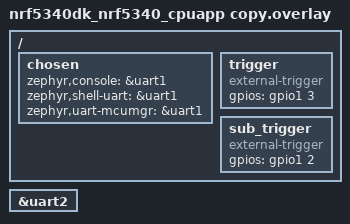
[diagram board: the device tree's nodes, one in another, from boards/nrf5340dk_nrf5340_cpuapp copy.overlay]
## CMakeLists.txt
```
# SPDX-License-Identifier: Apache-2.0

cmake_minimum_required(VERSION 3.20.0)

find_package(Zephyr REQUIRED HINTS $ENV{ZEPHYR_BASE})
project(ceva)

FILE(GLOB app_sources src/*.c)
target_sources(app PRIVATE ${app_sources})
```

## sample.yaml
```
sample:
  name: CEVA application
tests:
  applications.ceva:
    integration_platforms:
      - qemu_x86
    tags:
      - serial
      - uart
    filter: CONFIG_SERIAL and
            CONFIG_UART_INTERRUPT_DRIVEN and
            dt_chosen_enabled("zephyr,shell-uart")
    harness: keyboard
```

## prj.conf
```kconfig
CONFIG_CRYPTO=y
CONFIG_SERIAL=y
CONFIG_GPIO=y
CONFIG_UART_INTERRUPT_DRIVEN=y
CONFIG_NEWLIB_LIBC=y
CONFIG_MAIN_STACK_SIZE=4096
CONFIG_BOOT_BANNER=n

CONFIG_MBEDTLS=y
CONFIG_MBEDTLS_BUILTIN=y
CONFIG_MBEDTLS_HEAP_SIZE=512
CONFIG_MBEDTLS_CIPHER_CCM_ENABLED=y
CONFIG_MBEDTLS_CIPHER_GCM_ENABLED=y
CONFIG_CRYPTO_MBEDTLS_SHIM=y


# CONFIG_BOARD_ENABLE_DCDC_APP=n 
# CONFIG_BOARD_ENABLE_DCDC_NET=n 
# CONFIG_BOARD_ENABLE_DCDC_HV=n 
```

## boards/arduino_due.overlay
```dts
/*
 * Copyright (c) 2023 Laurent Bonnet
 *
 * SPDX-License-Identifier: Apache-2.0
 */

/**
 * trigger 0 = D12, PD8 
 * trigger 1 = D11, PD7
 */

/ {
	trigger: trigger {
		compatible = "external-trigger";
		gpios = <&piod 8 0>;
	};
	sub_trigger: sub_trigger {
		compatible = "external-trigger";
		gpios = <&piod 7 0>;
	};	
};

&piod {
	status="okay";
};
```

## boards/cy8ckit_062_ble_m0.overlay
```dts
/*
 * Copyright (c) 2023 Laurent Bonnet
 *
 * SPDX-License-Identifier: Apache-2.0
 */

/*
 * Map trigger to D7 in arduino header 
 * Refer to cy8ckit_062_common.dtsi
 */

/ {
	trigger: trigger {
		compatible = "external-trigger";
		gpios = <&gpio_prt0 2 GPIO_ACTIVE_HIGH>;
	};
	sub_trigger: sub_trigger {
		compatible = "external-trigger";
		gpios = <&gpio_prt0 3 GPIO_ACTIVE_HIGH>;
	};	
};
```

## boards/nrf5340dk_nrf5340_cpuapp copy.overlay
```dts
/*
 * Copyright (c) 2023 Laurent Bonnet
 *
 * SPDX-License-Identifier: Apache-2.0
 */

/ {
	chosen {
		zephyr,console = &uart1;
		zephyr,shell-uart = &uart1;
		zephyr,uart-mcumgr = &uart1;
	};
	
	trigger: trigger {
		compatible = "external-trigger";
		gpios = <&gpio1 3 GPIO_ACTIVE_HIGH>;
	};
	sub_trigger: sub_trigger {
		compatible = "external-trigger";
		gpios = <&gpio1 2 GPIO_ACTIVE_HIGH>;
	};	
};

&uart2 {
	status="okay";
};
```

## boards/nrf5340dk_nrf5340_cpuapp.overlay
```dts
/*
 * Copyright (c) 2023 Laurent Bonnet
 *
 * SPDX-License-Identifier: Apache-2.0
 */

/ {
	chosen {
		zephyr,console = &uart1;
		zephyr,shell-uart = &uart1;
		zephyr,uart-mcumgr = &uart1;
	};

	trigger: trigger {
		compatible = "external-trigger";
		gpios = <&gpio1 3 GPIO_ACTIVE_HIGH>;
	};
	sub_trigger: sub_trigger {
		compatible = "external-trigger";
		gpios = <&gpio1 2 GPIO_ACTIVE_HIGH>;
	};	
};

&uart1 {
	status="okay";
};
```

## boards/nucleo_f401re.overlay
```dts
/*
 * Copyright (c) 2023 Laurent Bonnet
 *
 * SPDX-License-Identifier: Apache-2.0
 */

/**
 * trigger 0 = D10, PB6  CN5.3
 * trigger 1 = D6,  PB10 CN9.7
 */

/ {
	trigger: trigger {
		compatible = "external-trigger";
		gpios = <&gpiob 6 GPIO_ACTIVE_HIGH>;
	};
	sub_trigger: sub_trigger {
		compatible = "external-trigger";
		gpios = <&gpiob 10 GPIO_ACTIVE_HIGH>;
	};
};
```

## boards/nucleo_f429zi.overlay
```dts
/*
 * Copyright (c) 2023 Laurent Bonnet
 *
 * SPDX-License-Identifier: Apache-2.0
 */

/**
 * trigger 0 = D28, PD13  CN10.19
 * trigger 1 = D30,  PD11  CN10.23
 */

/ {
	trigger: trigger {
		compatible = "external-trigger";
		gpios = <&gpiod 13 GPIO_ACTIVE_HIGH>;
	};
	sub_trigger: sub_trigger {
		compatible = "external-trigger";
		gpios = <&gpiod 11 GPIO_ACTIVE_HIGH>;
	};
};
```

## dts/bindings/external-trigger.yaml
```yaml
# Copyright (c) 2023 Laurent Bonnet
# SPDX-License-Identifier: Apache-2.0

description: GPIO pin to trigger external equipment

compatible: "external-trigger"

properties:
  gpios:
    type: phandle-array
    required: true
    description: |
      The GPIO used to trigger external equipment
```

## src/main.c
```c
/*
 * Copyright (c) 2023 Laurent Woolcap
 *
 * SPDX-License-Identifier: Apache-2.0
 */
#include <zephyr/device.h>
#include <zephyr/kernel.h>
#include <zephyr/sys/sys_heap.h>
#include <zephyr/kernel_version.h>
#include <zephyr/drivers/uart.h>
#include <zephyr/crypto/crypto.h>
#include <zephyr/drivers/gpio.h>

#include <string.h>
#include <stdio.h>
#include "main.h"
#include "simply_aes.h"
#include "utils.h"

#ifdef CONFIG_CRYPTO_TINYCRYPT_SHIM
#define CRYPTO_DRV_NAME CONFIG_CRYPTO_TINYCRYPT_SHIM_DRV_NAME
#elif CONFIG_CRYPTO_MBEDTLS_SHIM
#define CRYPTO_DRV_NAME CONFIG_CRYPTO_MBEDTLS_SHIM_DRV_NAME
#elif DT_HAS_COMPAT_STATUS_OKAY(st_stm32_cryp)
#define CRYPTO_DEV_COMPAT st_stm32_cryp
#elif DT_HAS_COMPAT_STATUS_OKAY(st_stm32_aes)
#define CRYPTO_DEV_COMPAT st_stm32_aes
#elif DT_HAS_COMPAT_STATUS_OKAY(nxp_mcux_dcp)
#define CRYPTO_DEV_COMPAT nxp_mcux_dcp
#elif CONFIG_CRYPTO_NRF_ECB
#define CRYPTO_DEV_COMPAT nordic_nrf_ecb
#else
#error "You need to enable one crypto device"
#endif

/* change this to any other UART peripheral if desired */
#define UART_DEVICE_NODE DT_CHOSEN(zephyr_shell_uart)

/* Message size in characters*/
#define MSG_CHAR_SIZE 512
#define MSG_BYTE_SIZE (MSG_CHAR_SIZE	>>	2)
#define MSG_WORD_SIZE (MSG_BYTE_SIZE	>>	2)

#define version "0.1.0"

/* queue to store up to 10 messages (aligned to 4-byte boundary) */
K_MSGQ_DEFINE(uart_msgq, MSG_CHAR_SIZE, 10, 4);

static const struct device *const uart_dev = DEVICE_DT_GET(UART_DEVICE_NODE);

/* device tree for led */
#define LED0_NODE DT_ALIAS(led0)
static const struct gpio_dt_spec led = GPIO_DT_SPEC_GET(LED0_NODE, gpios);

/* receive buffer used in UART ISR callback */
static char rx_buf[MSG_CHAR_SIZE];
static int rx_buf_pos;
uint32_t cap_flags;
const struct device *dev;

/**
 * @brief header structure 
 */
struct header {
	uint8_t cla;
	uint8_t ins;
	uint8_t p1;	
	uint8_t p2;
	uint16_t length;
	union  {
		uint8_t byte[MSG_BYTE_SIZE - 6];
		uint16_t word[MSG_WORD_SIZE - 3];
	} data;
};

struct header * command;
uint8_t out[MSG_BYTE_SIZE];

/**
 * @brief swap 16bit value
 * @param val input value
 * @return uint16_t 
 */
uint16_t swap16(uint16_t val) {
    return ((val << 8) | (val >> 8 ));
}

/**
 * @brief Read characters from UART until line end is detected. Afterwards push the
 * data to the message queue.
 * @param dev pointer on device
 * @param user_data pointer on message data
 */
void read(const struct device *dev, void *user_data) {
	uint8_t c;

	if (!uart_irq_update(uart_dev)) {
		return;
	}

	if (!uart_irq_rx_ready(uart_dev)) {
		return;
	}

	/* read until FIFO empty */
	while (uart_fifo_read(uart_dev, &c, 1) == 1) {
		if ((c == '\n' || c == '\r') && rx_buf_pos > 0) {
			/* terminate string */
			rx_buf[rx_buf_pos] = '\0';

			/* if queue is full, message is silently dropped */
			k_msgq_put(&uart_msgq, &rx_buf, K_NO_WAIT);

			/* reset the buffer (it was copied to the msgq) */
			rx_buf_pos = 0;
		} else if (rx_buf_pos < (sizeof(rx_buf) - 1)) {
			rx_buf[rx_buf_pos++] = c;
		}
		/* else: characters beyond buffer size are dropped */
	}
}

/**
 * @brief a null-terminated string character by character to the UART interface
 * @param buf pointer on output buffer
 */
void send(char *buf) {
	int lenght = strlen(buf);
	for (int i = 0; i < lenght; i++) {
		uart_poll_out(uart_dev, buf[i]);
	}
}

/**
 * @brief basic check of the command string, and byte convertion
 * @param in pointer on input string
 * @param out pointer on output byte array.
 */
int check(char *in, uint8_t *out) {
	// Get lenght
	int length = strlen(in);
	if ((length < 12) || (length % 2 != 0))
		return -1;
    for (int i = 0; i < length; i++)
    {
        // Reads in & stores in out
        sscanf(in, "%2hhx", &out[i]);
        in += 2;
    }
	// cast to header structure
 	command = (struct header * )out;
	// convert length
	command->length = swap16(command->length);
	// check length consistency with data received
	if (((length / 2) - command->length) != 6) {
		return -2;
	}
	return 0;
}

/**
 * @brief while loop command
 * @param iteration loop index max value
 */
void while_loop(uint16_t iteration) {
	uint16_t index, count = 0;
	char result[24];
	index = iteration;

	trigger_high();
	while(index) {
		index--;
		count++;
	}
	trigger_low();
	sprintf(result, "%04X%04X9000\r\n",index,count);
	send(result);
}

/**
 * @brief for loop command
 * @param iteration loop index max value
 */
void for_loop(uint16_t iteration) {
	char result[24];
	uint16_t index, count = 0;

	trigger_high();
	for (index = 0; index < iteration; index++) {
		count ++;
	}
	trigger_low();

	sprintf(result, "%04X%04X9000\r\n",index,count);
	send(result);
}

/**
 * @brief encrypt with simply aes command
 * @param data pointer on data in
 */
void simply_aes(uint8_t * data) {
	uint8_t result[2 * 16 + 4];
	uint8_t offset = 0;
	simple_aes_init(data);
	
	trigger_high();
	simple_aes_cipher();
	trigger_low();
	
	simple_aes_final(data);

	for (int i=0; i < 16; i++) {
		offset += sprintf(result + offset, "%02X", data[i]);
	}
	sprintf(result + offset, "9000\r\n");
	send(result);
}

/**
 *  @brief
 */
int validate_hw_compatibility(const struct device *dev)
{
	uint32_t flags = 0U;

	flags = crypto_query_hwcaps(dev);
	if ((flags & CAP_RAW_KEY) == 0U) {
		printk("Please provision the key separately as the module doesnt support a raw key");
		return -1;
	}

	if ((flags & CAP_SYNC_OPS) == 0U) {
		printk("The app assumes sync semantics. Please rewrite the app accordingly before proceeding");
		return -1;
	}

	if ((flags & CAP_SEPARATE_IO_BUFS) == 0U) {
		printk("The app assumes distinct IO buffers. Please rewrite the app accordingly before proceeding");
		return -1;
	}

	cap_flags = CAP_RAW_KEY | CAP_SYNC_OPS | CAP_SEPARATE_IO_BUFS;

	return 0;

}

/**
 * @brief aes encrypt ecb mode
 * @param data pointer data in
 */
void encrypt_aes_ebc(uint8_t * data) {
	uint8_t result[2 * 16 + 6];
	uint8_t offset = 0;
	uint8_t encrypted[16] = {0};

	struct cipher_ctx ini = {
		.keylen = 16,
		.key.bit_stream = data,
		.flags = cap_flags,
	};
	struct cipher_pkt encrypt = {
		.in_buf = &data[16],
		.in_len = 16,
		.out_buf_max = sizeof(encrypted),
		.out_buf = encrypted,
	};
	if (cipher_begin_session(dev, &ini, CRYPTO_CIPHER_ALGO_AES,
				 CRYPTO_CIPHER_MODE_ECB,
				 CRYPTO_CIPHER_OP_ENCRYPT)) {
		return;
	}
	trigger_high();
	if (cipher_block_op(&ini, &encrypt)) {
		goto out;
	}
	trigger_low();
	for (int i=0; i < 16; i++) {
		offset += sprintf(result + offset, "%02X", encrypt.out_buf[i]);
	}
	sprintf(result + offset, "9000\r\n");
	send(result);
out:
	cipher_free_session(dev, &ini);	
}

/**
 * @brief Dispatch command
 * @param pointer to input buffer
 */
int dispatch(char *in) {
	int status = 0;
	uint32_t v;

	// start watchdog

	// check input data
	status = check(in,out);
	
	if (status==0) {
		if (command->cla != CLASS)
			send("6E00\r\n");
		else {
			switch (command->ins) {
				case INS_GET_INFO:
					v = sys_kernel_version_get();

					printk("Chip evaluation Zephir Kernel= %d.%d.%d, board= %s, firmware version=%s\r\n", SYS_KERNEL_VER_MAJOR(v),SYS_KERNEL_VER_MINOR(v), SYS_KERNEL_VER_PATCHLEVEL(v),CONFIG_BOARD,version);
					break; 

				case INS_LOOP:
					if (command->length != 2)
						send("6700\r\n");
					else {
						if (command->p1==LOOP_FOR) {
							// call for loop process
							for_loop(command->data.word[0]);
						} else if (command->p1==LOOP_WHILE) {
							// call while loop process
							while_loop(command->data.word[0]);
						} else {
							send("6A00\r\n");
						}
					}
					break;
				case INS_CRYPTO:
					if (command->length != 32)
						send("6700\r\n");
					else
						if (command->p1==SIMPLY_ENCRYPT_AES_ECB) {
							simply_aes(command->data.byte);							
						} else if (command->p1==DRIVER_ENCRYPT_AES_ECB) {
							encrypt_aes_ebc(command->data.byte);
						} else {
							send("6A00\r\n");
						}
					break;

				default:
					send("6986\r\n");
					break;
			}
		}
	}
	if (status==-1) {
		send("6F01\r\n");
	}

	if (status==-2) {
		send("6700\r\n");
	}
	// stop watchdog
	
	return 0;
}

/**
 * 
 */
int main(void)
{
	char cmd_buf[MSG_CHAR_SIZE];

#ifdef CRYPTO_DRV_NAME
	dev = device_get_binding(CRYPTO_DRV_NAME);
	if (!dev) {
		printk("%s pseudo device not found", CRYPTO_DRV_NAME);
		return 0;
	}
#else
	dev = DEVICE_DT_GET_ONE(CRYPTO_DEV_COMPAT);

	if (!device_is_ready(dev)) {
		printk("Crypto device is not ready\n");
		return 0;
	}
#endif

	if (!device_is_ready(uart_dev)) {
		printk("UART device not found!");
		return 0;
	}
	if (validate_hw_compatibility(dev)) {
		printk("Incompatible crypto h/w");
		return 0;
	}
	/* configure interrupt and callback to receive data */
	int ret = uart_irq_callback_user_data_set(uart_dev, read, NULL);

	if (ret < 0) {
		if (ret == -ENOTSUP) {
			printk("Interrupt-driven UART API support not enabled\n");
		} else if (ret == -ENOSYS) {
			printk("UART device does not support interrupt-driven API\n");
		} else {
			printk("Error setting UART callback: %d\n", ret);
		}
		return 0;
	}

	uart_irq_rx_enable(uart_dev);

	/* Set led0 */
	if (!gpio_is_ready_dt(&led)) {
		printk("Error indicator not ready...");
		return 0;
	}

	ret = gpio_pin_configure_dt(&led, GPIO_OUTPUT_ACTIVE);
	if (ret < 0) {
		printk("Error indicator configuration...");
		return 0;
	}

	ret = gpio_pin_set_dt(&led, 1);
	if (ret < 0) {
		printk("Error indicator toggle...");
		return 0;
	}

	ret = trigger_init();
	if (ret < 0) {
		printk("Error trigger init...");
		return 0;
	}

	/* indefinitely wait for input from the user */
	while (k_msgq_get(&uart_msgq, &cmd_buf, K_FOREVER) == 0) {	
		dispatch(cmd_buf);
	}
	return 0;
}
```

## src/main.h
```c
/**
 * @file main.h
 * @author Laurent Bonnet (laurent.woolcap@free.fr)
 * @brief Chip evaluation firmware, main interface file
 * @copyright Copyright (c) 2024
 */
#define CLASS                   0xFE /*!< Command Class byte */

#define INS_GET_INFO            0x80 /*!< Get info instruction byte */

/**
 * @brief loop instructions
 */
#define INS_LOOP                0x86 /*!< Loop Instruction byte */
#define LOOP_FOR                0x02 /*!< P1 Parameter: for loop */
#define LOOP_WHILE              0x04 /*!< P1 Parameter: while loop */

/**
 * @brief Cryptographic instructions
 */
#define INS_CRYPTO              0x8A /*!< Crypto Instruction byte */
#define SIMPLY_ENCRYPT_AES_ECB  0x02 /*!< AES ECB SIMPLY */
#define DRIVER_ENCRYPT_AES_ECB  0x04 /*!< AES ECB MBEDTLS */
```

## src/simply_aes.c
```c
/**
 * @file simply_aes.c
 * @author laurent bonnet (laurent.woolcap@free.fr)
 * @brief Chip Evaluation firmware, Simple software AES
 * @copyright Copyright (c) 2023
 */
#define __UL_AES_C
#include "simply_aes.h"
#include "utils.h"

static  const int Sbox    [256] = _Sub;
const int xtimes  [256] = _xt;
static  const int rcon[10] = {0x01, 0x02, 0x04, 0x08, 0x10, 0x20, 0x40, 0x80, 0x1b, 0x36};
int rk[176];
int state[16];
int tmp[2];
int *pt_rk;

/**
 * @brief key expansion
 */
static void key_expansion(void)
{
  int i;
  for(i=16;i<176;i+=4){
    
    if ((i&0xF)==0){
      state[0] = Sbox[rk[i-3]] ^ rcon[(i/16)-1];
      state[1] = Sbox[rk[i-2]];
      state[2] = Sbox[rk[i-1]];
      state[3] = Sbox[rk[i-4]];
    }
    
    else{
      state[0] = rk[i-4];
      state[1] = rk[i-3];
      state[2] = rk[i-2];
      state[3] = rk[i-1];
    }
    
    rk[i  ] = rk[i-16] ^ state[0];
    rk[i+1] = rk[i-15] ^ state[1];
    rk[i+2] = rk[i-14] ^ state[2];
    rk[i+3] = rk[i-13] ^ state[3];
  }
}

/**
 * @brief Add round Key
 */
static void AddRoundKey(void)
{
  int j;
  for(j=0;j<16;j++){
    state[j] ^= pt_rk[j];
  }
}

/**
 * @brief subbytes and shiftrow operation
 */
static void SubBytes_ShiftRows(void)
{
  state[ 0] = Sbox[state[ 0]];
  state[ 4] = Sbox[state[ 4]];
  state[ 8] = Sbox[state[ 8]];
  state[12] = Sbox[state[12]];

  tmp[0]    = Sbox[state[ 1]];
  state[ 1] = Sbox[state[ 5]];
  state[ 5] = Sbox[state[ 9]];
  state[ 9] = Sbox[state[13]];
  state[13] = tmp[0];
    
  tmp[0]    = Sbox[state[ 2]];
  state[ 2] = Sbox[state[10]];
  state[10] = tmp[0];

  tmp[0]    = Sbox[state[6]];
  state[ 6] = Sbox[state[14]];
  state[14] = tmp[0];

  tmp[0]    = Sbox[state[15]];
  state[15] = Sbox[state[11]];
  state[11] = Sbox[state[ 7]];
  state[7 ] = Sbox[state[ 3]];
  state[3 ] = tmp[0];
}

/**
 * @brief Execute round
 */
static void aes_round( void )
{
  int column[4]; // temporary variable to hold a column from the state

  pt_rk += 16;
  
  //SubBytes + ShiftRows
  SubBytes_ShiftRows();
  
  //MixColumns
  
  //column 0
  column[0] = state[0];
  column[1] = state[1];
  column[2] = state[2];
  column[3] = state[3];

  state[ 0] = mix_column(0,1,2,3);
  state[ 1] = mix_column(1,2,3,0);
  state[ 2] = mix_column(2,3,0,1);
  state[ 3] = mix_column(3,0,1,2);

  //column 1
  column[0] = state[4];
  column[1] = state[5];
  column[2] = state[6];
  column[3] = state[7];

  state[ 4] = mix_column(0,1,2,3);
  state[ 5] = mix_column(1,2,3,0);
  state[ 6] = mix_column(2,3,0,1);
  state[ 7] = mix_column(3,0,1,2);

  //column 2
  column[0] = state[ 8];
  column[1] = state[ 9];
  column[2] = state[10];
  column[3] = state[11];

  state[ 8] = mix_column(0,1,2,3);
  state[ 9] = mix_column(1,2,3,0);
  state[10] = mix_column(2,3,0,1);
  state[11] = mix_column(3,0,1,2);

  //column 3
  column[0] = state[12];
  column[1] = state[13];
  column[2] = state[14];
  column[3] = state[15];

  state[12] = mix_column(0,1,2,3);
  state[13] = mix_column(1,2,3,0);
  state[14] = mix_column(2,3,0,1);
  state[15] = mix_column(3,0,1,2);

  //AddRoundKey
  AddRoundKey();
}

/**
 * @brief AES Cipher
 */
void simple_aes_cipher()
{
  int i = 0;
  int ret = 0;

  //AddRoundKey
  pt_rk = rk;
  AddRoundKey();

  for(i=0; i<9; i++){
    if (i==8) {
      ret = sub_trigger_high();
      if (ret < 0) 
        return;
    }
    aes_round();
    if (i==8) {
      ret = sub_trigger_low();
      if (ret < 0) 
        return;
    }
  }
  
  //Last round 
  SubBytes_ShiftRows(); 
  pt_rk += 16;
  AddRoundKey();
}

/**
 * @brief AES initialization process
 * @param buffer pointer on input data
 */
 void simple_aes_init(uint8_t * buffer) {
    int i,j;
    for(i=0; i<16; i++){
        rk[i] = buffer[i];
    }

    key_expansion();

    pt_rk = rk;

    for(j=0; j<16; j++,i++){
        state[j] = buffer[i];
    }
}

/**
 * @brief AES final
 * @param result Pointer on result buffer
 */
void simple_aes_final(uint8_t * result) {
    uint8_t i;
    for (i=0;i<16;i++)
    {
      result[i]=state[i];
    }
}
```

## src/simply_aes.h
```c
/**
 * @file simply_aes.h.h
 * @author Laurent Bonnet (laurent.woolcap@free.fr)
 * @brief Chip evaluation firmware, simple aes interface file
 * @copyright Copyright (c) 2023
 */
#ifndef __SIMPLY_AES_H
#define __SIMPLY_AES_H

#ifdef __cplusplus
extern "C"
{
#endif

#include<stdint.h>

//*****************************************************************************
// Macro definitions
//*****************************************************************************
#define mix_column(a,b,c,d) (xtimes[ column[a] ^ column[b] ] ^ column[b] ^ column[c] ^ column[d])
#define inv_mixcolumn(a,b,c,d)  (x0e[column[a]]^x0b[column[b]]^x0d[column[c]]^x09[column[d]])

// Table pour 'xtimes'
#define _xt {0x0,0x2,0x4,0x6,0x8,0xa,0xc,0xe,0x10,0x12,0x14,0x16,0x18,0x1a,0x1c,0x1e,0x20,0x22,0x24,0x26,0x28,0x2a,0x2c,0x2e,0x30,0x32,0x34,0x36,0x38,0x3a,0x3c,0x3e,0x40,0x42,0x44,0x46,0x48,0x4a,0x4c,0x4e,0x50,0x52,0x54,0x56,0x58,0x5a,0x5c,0x5e,0x60,0x62,0x64,0x66,0x68,0x6a,0x6c,0x6e,0x70,0x72,0x74,0x76,0x78,0x7a,0x7c,0x7e,0x80,0x82,0x84,0x86,0x88,0x8a,0x8c,0x8e,0x90,0x92,0x94,0x96,0x98,0x9a,0x9c,0x9e,0xa0,0xa2,0xa4,0xa6,0xa8,0xaa,0xac,0xae,0xb0,0xb2,0xb4,0xb6,0xb8,0xba,0xbc,0xbe,0xc0,0xc2,0xc4,0xc6,0xc8,0xca,0xcc,0xce,0xd0,0xd2,0xd4,0xd6,0xd8,0xda,0xdc,0xde,0xe0,0xe2,0xe4,0xe6,0xe8,0xea,0xec,0xee,0xf0,0xf2,0xf4,0xf6,0xf8,0xfa,0xfc,0xfe,0x1b,0x19,0x1f,0x1d,0x13,0x11,0x17,0x15,0xb,0x9,0xf,0xd,0x3,0x1,0x7,0x5,0x3b,0x39,0x3f,0x3d,0x33,0x31,0x37,0x35,0x2b,0x29,0x2f,0x2d,0x23,0x21,0x27,0x25,0x5b,0x59,0x5f,0x5d,0x53,0x51,0x57,0x55,0x4b,0x49,0x4f,0x4d,0x43,0x41,0x47,0x45,0x7b,0x79,0x7f,0x7d,0x73,0x71,0x77,0x75,0x6b,0x69,0x6f,0x6d,0x63,0x61,0x67,0x65,0x9b,0x99,0x9f,0x9d,0x93,0x91,0x97,0x95,0x8b,0x89,0x8f,0x8d,0x83,0x81,0x87,0x85,0xbb,0xb9,0xbf,0xbd,0xb3,0xb1,0xb7,0xb5,0xab,0xa9,0xaf,0xad,0xa3,0xa1,0xa7,0xa5,0xdb,0xd9,0xdf,0xdd,0xd3,0xd1,0xd7,0xd5,0xcb,0xc9,0xcf,0xcd,0xc3,0xc1,0xc7,0xc5,0xfb,0xf9,0xff,0xfd,0xf3,0xf1,0xf7,0xf5,0xeb,0xe9,0xef,0xed,0xe3,0xe1,0xe7,0xe5}

// table pour SubBytes
#define _Sub {                      \
    0x63, 0x7C, 0x77, 0x7B, 0xF2, 0x6B, 0x6F, 0xC5,\
    0x30, 0x01, 0x67, 0x2B, 0xFE, 0xD7, 0xAB, 0x76,\
    0xCA, 0x82, 0xC9, 0x7D, 0xFA, 0x59, 0x47, 0xF0,\
    0xAD, 0xD4, 0xA2, 0xAF, 0x9C, 0xA4, 0x72, 0xC0,\
    0xB7, 0xFD, 0x93, 0x26, 0x36, 0x3F, 0xF7, 0xCC,\
    0x34, 0xA5, 0xE5, 0xF1, 0x71, 0xD8, 0x31, 0x15,\
    0x04, 0xC7, 0x23, 0xC3, 0x18, 0x96, 0x05, 0x9A,\
    0x07, 0x12, 0x80, 0xE2, 0xEB, 0x27, 0xB2, 0x75,\
    0x09, 0x83, 0x2C, 0x1A, 0x1B, 0x6E, 0x5A, 0xA0,\
    0x52, 0x3B, 0xD6, 0xB3, 0x29, 0xE3, 0x2F, 0x84,\
    0x53, 0xD1, 0x00, 0xED, 0x20, 0xFC, 0xB1, 0x5B,\
    0x6A, 0xCB, 0xBE, 0x39, 0x4A, 0x4C, 0x58, 0xCF,\
    0xD0, 0xEF, 0xAA, 0xFB, 0x43, 0x4D, 0x33, 0x85,\
    0x45, 0xF9, 0x02, 0x7F, 0x50, 0x3C, 0x9F, 0xA8,\
    0x51, 0xA3, 0x40, 0x8F, 0x92, 0x9D, 0x38, 0xF5,\
    0xBC, 0xB6, 0xDA, 0x21, 0x10, 0xFF, 0xF3, 0xD2,\
    0xCD, 0x0C, 0x13, 0xEC, 0x5F, 0x97, 0x44, 0x17,\
    0xC4, 0xA7, 0x7E, 0x3D, 0x64, 0x5D, 0x19, 0x73,\
    0x60, 0x81, 0x4F, 0xDC, 0x22, 0x2A, 0x90, 0x88,\
    0x46, 0xEE, 0xB8, 0x14, 0xDE, 0x5E, 0x0B, 0xDB,\
    0xE0, 0x32, 0x3A, 0x0A, 0x49, 0x06, 0x24, 0x5C,\
    0xC2, 0xD3, 0xAC, 0x62, 0x91, 0x95, 0xE4, 0x79,\
    0xE7, 0xC8, 0x37, 0x6D, 0x8D, 0xD5, 0x4E, 0xA9,\
    0x6C, 0x56, 0xF4, 0xEA, 0x65, 0x7A, 0xAE, 0x08,\
    0xBA, 0x78, 0x25, 0x2E, 0x1C, 0xA6, 0xB4, 0xC6,\
    0xE8, 0xDD, 0x74, 0x1F, 0x4B, 0xBD, 0x8B, 0x8A,\
    0x70, 0x3E, 0xB5, 0x66, 0x48, 0x03, 0xF6, 0x0E,\
    0x61, 0x35, 0x57, 0xB9, 0x86, 0xC1, 0x1D, 0x9E,\
    0xE1, 0xF8, 0x98, 0x11, 0x69, 0xD9, 0x8E, 0x94,\
    0x9B, 0x1E, 0x87, 0xE9, 0xCE, 0x55, 0x28, 0xDF,\
    0x8C, 0xA1, 0x89, 0x0D, 0xBF, 0xE6, 0x42, 0x68,\
    0x41, 0x99, 0x2D, 0x0F, 0xB0, 0x54, 0xBB, 0x16 }

//*****************************************************************************
// External function definitions
//*****************************************************************************
extern void simple_aes_cipher(void);
extern void simple_aes_init(uint8_t *message);
extern void simple_aes_final(uint8_t *result);

#ifdef __cplusplus
}
#endif

#endif // __SIMPLY_AES_H
```

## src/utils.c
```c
/**
 * @file utils.c
 * @author Laurent Bonnet (laurent.woolcap@free.fr)
 * @brief Chip evaluation firmware, utility toolbox
 * @copyright Copyright (c) 2023
 */
#include <stdio.h>
#include <zephyr/kernel.h>
#include <zephyr/devicetree.h>
#include <zephyr/drivers/gpio.h>



/* device tree for trigger */
#if !DT_NODE_EXISTS(DT_NODELABEL(trigger))
#error "Overlay for trigger output node not properly defined."
#endif

#if !DT_NODE_EXISTS(DT_NODELABEL(sub_trigger))
#error "Overlay for sub trigger output node not properly defined."
#endif

static const struct gpio_dt_spec trigger = GPIO_DT_SPEC_GET_OR(DT_NODELABEL(trigger), gpios, {0});
static const struct gpio_dt_spec sub_trigger = GPIO_DT_SPEC_GET_OR(DT_NODELABEL(sub_trigger), gpios, {0});

int trigger_init(void) {
    int ret;
    
	ret = gpio_is_ready_dt(&trigger);
    if (ret < 0) {
		return ret;
	}
    ret = gpio_pin_configure_dt(&trigger, GPIO_OUTPUT_INACTIVE);
    if (ret < 0) {
        return ret;
	}
	ret = gpio_is_ready_dt(&sub_trigger);
    if (ret < 0) {
		return ret;
	}
    ret = gpio_pin_configure_dt(&sub_trigger, GPIO_OUTPUT_INACTIVE);
    if (ret < 0) {
        return ret;
	}
    return 0;
}

/**
 * @brief set trigger high
 */
int trigger_high(void) {
    return gpio_pin_set_dt(&trigger,1);
}

/**
 * @brief set trigger low
 */
int trigger_low(void) {
    return gpio_pin_set_dt(&trigger,0);
}

/**
 * @brief set sub trigger high
 */
int sub_trigger_high(void) {
    return gpio_pin_set_dt(&sub_trigger,1);
}

/**
 * @brief set sub trigger low
 */
int sub_trigger_low(void) {
    return gpio_pin_set_dt(&sub_trigger,0);
}
```

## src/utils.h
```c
/**
 * @file utils.h
 * @author Laurent Bonnet (laurent.woolcap@free.fr)
 * @brief Chip evaluation firmware, utils interface file
 * @copyright Copyright (c) 2023
 */
#ifndef __UTILS_H
#define __UTILS_H

#ifdef __cplusplus
extern "C"
{
#endif

extern int trigger_init(void);
extern int trigger_low(void);
extern int trigger_high(void);
extern int sub_trigger_low(void);
extern int sub_trigger_high(void);
#ifdef __cplusplus
}
#endif

#endif // __UTILS_H
```
